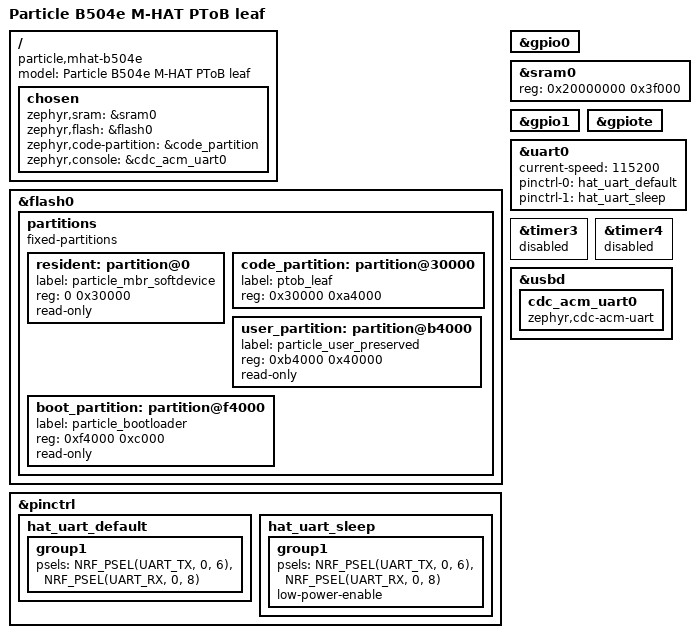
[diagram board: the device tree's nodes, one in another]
// Copyright (c) 2026 Jonathan Yantis. SPDX-License-Identifier: MIT
/dts-v1/;
#include <nordic/nrf52840_qiaa.dtsi>
#include <zephyr/dt-bindings/gpio/gpio.h>
#include <zephyr/dt-bindings/pinctrl/nrf-pinctrl.h>
/ {
    model = "Particle B504e M-HAT PToB leaf";
    compatible = "particle,mhat-b504e";
    chosen {
        zephyr,sram = &sram0;
        zephyr,flash = &flash0;
        zephyr,code-partition = &code_partition;
        zephyr,console = &cdc_acm_uart0;
    };
};
&flash0 {
    partitions {
        compatible = "fixed-partitions";
        #address-cells = <1>;
        #size-cells = <1>;
        resident: partition@0 { label = "particle_mbr_softdevice"; reg = <0 0x30000>; read-only; };
        code_partition: partition@30000 { label = "ptob_leaf"; reg = <0x30000 0xa4000>; };
        user_partition: partition@b4000 { label = "particle_user_preserved"; reg = <0xb4000 0x40000>; read-only; };
        boot_partition: partition@f4000 { label = "particle_bootloader"; reg = <0xf4000 0xc000>; read-only; };
    };
};
&gpio0 { status = "okay"; };
/* Particle's bootloader owns retained flags/registers in the top 4 KiB. */
&sram0 { reg = <0x20000000 0x3f000>; };
&gpio1 { status = "okay"; };
&gpiote { status = "okay"; };
&pinctrl {
    hat_uart_default: hat_uart_default {
        group1 { psels = <NRF_PSEL(UART_TX, 0, 6)>, <NRF_PSEL(UART_RX, 0, 8)>; };
    };
    hat_uart_sleep: hat_uart_sleep {
        group1 { psels = <NRF_PSEL(UART_TX, 0, 6)>, <NRF_PSEL(UART_RX, 0, 8)>; low-power-enable; };
    };
};
&uart0 {
    status = "okay";
    current-speed = <115200>;
    pinctrl-0 = <&hat_uart_default>;
    pinctrl-1 = <&hat_uart_sleep>;
    pinctrl-names = "default", "sleep";
    /* No RTS/CTS: D2/P1.02 is dedicated to PPS. */
};
&timer3 { status = "disabled"; };
&timer4 { status = "disabled"; };
&usbd {
    status = "okay";
    cdc_acm_uart0: cdc_acm_uart0 { compatible = "zephyr,cdc-acm-uart"; };
};
